AUTOSAR XML (schema 4-2-2)
package /ComponentTypes
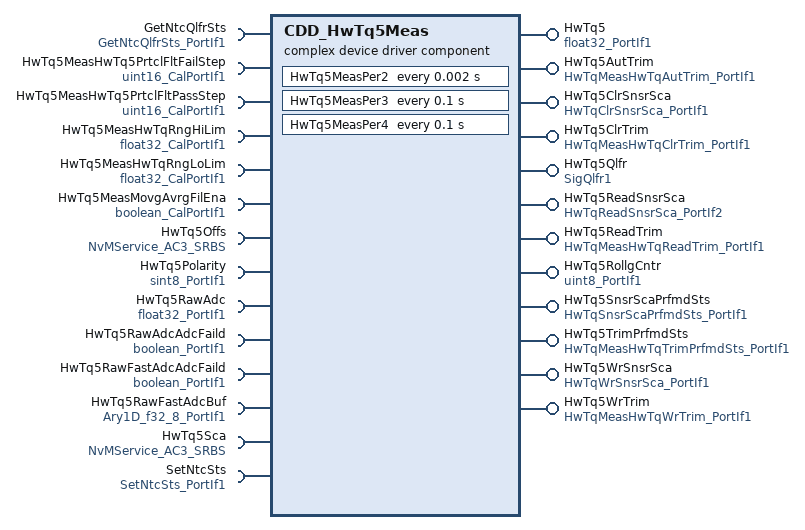
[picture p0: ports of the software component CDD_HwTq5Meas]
  complex device driver sw component type CDD_HwTq5Meas
    12 x provide port:
      HwTq5: nonqueued-sender-com-spec{data-element=Val, init-value=0}, provided-interface=float32_PortIf1
      HwTq5AutTrim: server-com-spec{operation=Oper, queue-length=1}, provided-interface=HwTqMeasHwTqAutTrim_PortIf1
      HwTq5ClrSnsrSca: server-com-spec{operation=Oper, queue-length=1}, provided-interface=HwTqClrSnsrSca_PortIf1
      HwTq5ClrTrim: server-com-spec{operation=Oper, queue-length=1}, provided-interface=HwTqMeasHwTqClrTrim_PortIf1
      HwTq5Qlfr: nonqueued-sender-com-spec{data-element=Val, init-value=0}, provided-interface=SigQlfr1
      HwTq5ReadSnsrSca: server-com-spec{operation=Oper, queue-length=1}, provided-interface=HwTqReadSnsrSca_PortIf2
      HwTq5ReadTrim: server-com-spec{operation=Oper, queue-length=1}, provided-interface=HwTqMeasHwTqReadTrim_PortIf1
      HwTq5RollgCntr: nonqueued-sender-com-spec{data-element=Val, init-value=0}, provided-interface=uint8_PortIf1
      HwTq5SnsrScaPrfmdSts: server-com-spec{operation=Oper, queue-length=1}, provided-interface=HwTqSnsrScaPrfmdSts_PortIf1
      HwTq5TrimPrfmdSts: server-com-spec{operation=Oper, queue-length=1}, provided-interface=HwTqMeasHwTqTrimPrfmdSts_PortIf1
      HwTq5WrSnsrSca: server-com-spec{operation=Oper, queue-length=1}, provided-interface=HwTqWrSnsrSca_PortIf1
      HwTq5WrTrim: server-com-spec{operation=Oper, queue-length=1}, provided-interface=HwTqMeasHwTqWrTrim_PortIf1
    14 x require port:
      GetNtcQlfrSts: client-com-spec=Oper, required-interface=GetNtcQlfrSts_PortIf1
      HwTq5MeasHwTq5PrtclFltFailStep: parameter-require-com-spec{init-value=2521, parameter=Val}, required-interface=uint16_CalPortIf1
      HwTq5MeasHwTq5PrtclFltPassStep: parameter-require-com-spec{init-value=1000, parameter=Val}, required-interface=uint16_CalPortIf1
      HwTq5MeasHwTqRngHiLim: parameter-require-com-spec{init-value=4.75, parameter=Val}, required-interface=float32_CalPortIf1
      HwTq5MeasHwTqRngLoLim: parameter-require-com-spec{init-value=0.25, parameter=Val}, required-interface=float32_CalPortIf1
      HwTq5MeasMovgAvrgFilEna: parameter-require-com-spec{init-value=0, parameter=Logl}, required-interface=boolean_CalPortIf1
      HwTq5Offs: required-com-specs=[EraseBlock, GetErrorStatus, InvalidateNvBlock, ReadBlock, SetRamBlockStatus, WriteBlock], required-interface=NvMService_AC3_SRBS
      HwTq5Polarity: nonqueued-receiver-com-spec{data-element=Val, filter=data-filter-type=ALWAYS, init-value=1}, required-interface=sint8_PortIf1
      HwTq5RawAdc: nonqueued-receiver-com-spec{data-element=Val, filter=data-filter-type=ALWAYS, init-value=0}, required-interface=float32_PortIf1
      HwTq5RawAdcAdcFaild: nonqueued-receiver-com-spec{data-element=Logl, filter=data-filter-type=ALWAYS, init-value=0}, required-interface=boolean_PortIf1
      HwTq5RawFastAdcAdcFaild: nonqueued-receiver-com-spec{data-element=Logl, filter=data-filter-type=ALWAYS, init-value=0}, required-interface=boolean_PortIf1
      HwTq5RawFastAdcBuf: nonqueued-receiver-com-spec{data-element=Ary1D, filter=data-filter-type=ALWAYS, init-value=8 x 0}, required-interface=Ary1D_f32_8_PortIf1
      HwTq5Sca: required-com-specs=[EraseBlock, GetErrorStatus, InvalidateNvBlock, ReadBlock, SetRamBlockStatus, WriteBlock], required-interface=NvMService_AC3_SRBS
      SetNtcSts: client-com-spec=Oper, required-interface=SetNtcSts_PortIf1
    behavior CDD_HwTq5Meas_InternalBehavior
      ar-typed-per-instance-memorys:
        5 x data, all with sw-calibration-access=READ-ONLY:
          HwTq5Offs: type=HwTqOffsRec1
          HwTq5PrevHwTq5: type=float32
          HwTq5PrevRollgCntr: type=uint8
          HwTq5RawFastAdcIdxCntr: type=uint8
          HwTq5Sca: type=AnHwTqScaFacRec1
      operation invoked event OIT_HwTq5AutTrim_Oper_HwTq5AutTrim_Oper: start-on-event=HwTq5AutTrim_Oper, operation=HwTq5AutTrim.Oper
      operation invoked event OIT_HwTq5ClrSnsrSca_Oper_HwTq5ClrSnsrSca_Oper: start-on-event=HwTq5ClrSnsrSca_Oper, operation=HwTq5ClrSnsrSca.Oper
      operation invoked event OIT_HwTq5ClrTrim_Oper_HwTq5ClrTrim_Oper: start-on-event=HwTq5ClrTrim_Oper, operation=HwTq5ClrTrim.Oper
      init event HwTq5Meas_InitEvent: start-on-event=HwTq5MeasInit1
      timing event TMT_HwTq5MeasPer2: start-on-event=HwTq5MeasPer2, period=0.002
      timing event TMT_HwTq5MeasPer3: start-on-event=HwTq5MeasPer3, period=0.1
      timing event TMT_HwTq5MeasPer4: start-on-event=HwTq5MeasPer4, period=0.1
      6 x operation invoked event:
        OIT_HwTq5ReadSnsrSca_Oper_HwTq5ReadSnsrSca_Oper: start-on-event=HwTq5ReadSnsrSca_Oper, operation=HwTq5ReadSnsrSca.Oper
        OIT_HwTq5ReadTrim_Oper_HwTq5ReadTrim_Oper: start-on-event=HwTq5ReadTrim_Oper, operation=HwTq5ReadTrim.Oper
        OIT_HwTq5SnsrScaPrfmdSts_Oper_HwTq5SnsrScaPrfmdSts_Oper: start-on-event=HwTq5SnsrScaPrfmdSts_Oper, operation=HwTq5SnsrScaPrfmdSts.Oper
        OIT_HwTq5TrimPrfmdSts_Oper_HwTq5TrimPrfmdSts_Oper: start-on-event=HwTq5TrimPrfmdSts_Oper, operation=HwTq5TrimPrfmdSts.Oper
        OIT_HwTq5WrSnsrSca_Oper_HwTq5WrSnsrSca_Oper: start-on-event=HwTq5WrSnsrSca_Oper, operation=HwTq5WrSnsrSca.Oper
        OIT_HwTq5WrTrim_Oper_HwTq5WrTrim_Oper: start-on-event=HwTq5WrTrim_Oper, operation=HwTq5WrTrim.Oper
      13 x runnable:
        HwTq5AutTrim_Oper
          sync call SC_HwTq5Offs_SetRamBlockStatus: operation=HwTq5Offs.SetRamBlockStatus, timeout=0
        HwTq5ClrSnsrSca_Oper
          sync call SC_HwTq5Sca_SetRamBlockStatus: operation=HwTq5Sca.SetRamBlockStatus, timeout=0
        HwTq5ClrTrim_Oper
          sync call SC_HwTq5Offs_SetRamBlockStatus: operation=HwTq5Offs.SetRamBlockStatus, timeout=0
        HwTq5MeasInit1
          sync call SC_HwTq5Offs_GetErrorStatus: operation=HwTq5Offs.GetErrorStatus, timeout=0
          sync call SC_HwTq5Sca_GetErrorStatus: operation=HwTq5Sca.GetErrorStatus, timeout=0
        HwTq5MeasPer2
          data-receive-point-by-arguments:
            5 x access:
              REC_HwTq5FastAdcBuf_Ary1D: accessed-variable=HwTq5RawFastAdcBuf.Ary1D
              REC_HwTq5Polarity_Val: accessed-variable=HwTq5Polarity.Val
              REC_HwTq5RawAdc_Val: accessed-variable=HwTq5RawAdc.Val
              REC_HwTq5RawAdcAdcFaild_Logl: accessed-variable=HwTq5RawAdcAdcFaild.Logl
              REC_HwTq5RawFastAdcAdcFaild_Logl: accessed-variable=HwTq5RawFastAdcAdcFaild.Logl
          data-send-points:
            access SEND_HwTq5_Val: accessed-variable=HwTq5.Val
            access SEND_HwTq5Qlfr_Val: accessed-variable=HwTq5Qlfr.Val
            access SEND_HwTq5RollgCntr_Val: accessed-variable=HwTq5RollgCntr.Val
          sync call SC_GetNtcQlfrSts_Oper: operation=GetNtcQlfrSts.Oper, timeout=0
          sync call SC_SetNtcSts_Oper: operation=SetNtcSts.Oper, timeout=0
        HwTq5MeasPer3
          sync call SC_SetNtcSts_Oper: operation=SetNtcSts.Oper, timeout=0
        HwTq5MeasPer4
          sync call SC_SetNtcSts_Oper: operation=SetNtcSts.Oper, timeout=0
        HwTq5ReadSnsrSca_Oper
        HwTq5ReadTrim_Oper
        HwTq5SnsrScaPrfmdSts_Oper
        HwTq5TrimPrfmdSts_Oper
        HwTq5WrSnsrSca_Oper
          sync call SC_HwTq5Sca_SetRamBlockStatus: operation=HwTq5Sca.SetRamBlockStatus, timeout=0
        HwTq5WrTrim_Oper
          sync call SC_HwTq5Offs_SetRamBlockStatus: operation=HwTq5Offs.SetRamBlockStatus, timeout=0
      swc service dependency NvmHwTq5Offs: assigned-datas=role-based-data-assignment={role=ramBlock, used-data-element=HwTq5Offs}, assigned-ports=role-based-port-assignment={port-prototype=HwTq5Offs, role=NvMService_AC3_SRBS}
        service-needs:
          nv block needs NvmHwTq5Offs: n-data-sets=0, ram-block-status-control=API, readonly=false, reliability=ERROR-DETECTION, resistant-to-changed-sw=true, restore-at-start=true, store-at-shutdown=true, write-only-once=false, writing-frequency=0, writing-priority=LOW
      swc service dependency NvmHwTq5Sca: assigned-datas=role-based-data-assignment={role=ramBlock, used-data-element=HwTq5Sca}, assigned-ports=role-based-port-assignment={port-prototype=HwTq5Sca, role=NvMService_AC3_SRBS}
        service-needs:
          nv block needs NvmHwTq5Sca: n-data-sets=0, ram-block-status-control=API, readonly=false, reliability=ERROR-DETECTION, resistant-to-changed-sw=true, restore-at-start=true, store-at-shutdown=true, write-only-once=false, writing-frequency=0, writing-priority=LOW
  swc implementation CDD_HwTq5Meas_Implementation: behavior=CDD_HwTq5Meas_InternalBehavior
    code-descriptors:
      code Default: artifact-descriptors=autosar-engineering-object={short-label=Default, category=SWSRC}
